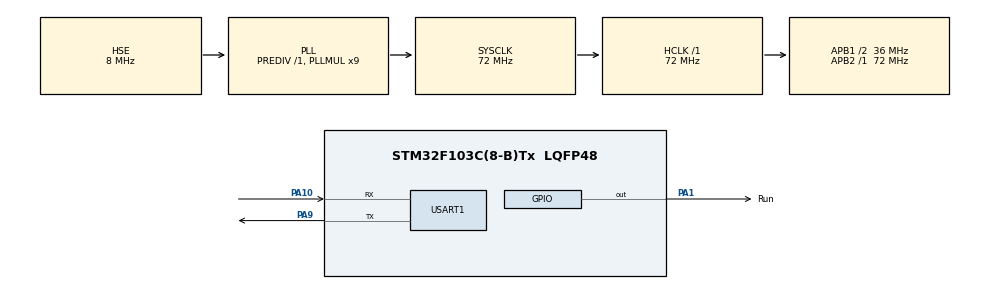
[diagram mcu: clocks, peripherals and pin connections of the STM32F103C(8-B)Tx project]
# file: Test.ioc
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Mcu.Family=STM32F1
Mcu.Name=STM32F103C(8-B)Tx
Mcu.Package=LQFP48
NVIC.PriorityGroup=NVIC_PRIORITYGROUP_4
NVIC.USART1_IRQn=true\:0\:0\:false\:false\:true\:true\:true\:true
PA1.GPIO_Label=Run
PA1.GPIO_ModeDefaultOutputPP=GPIO_MODE_OUTPUT_PP
PA1.GPIO_PuPd=GPIO_NOPULL
PA1.Signal=GPIO_Output
PA10.Mode=Asynchronous
PA10.Signal=USART1_RX
PA13.Mode=JTAG_4_pins
PA13.Signal=SYS_JTMS-SWDIO
PA14.Mode=JTAG_4_pins
PA14.Signal=SYS_JTCK-SWCLK
PA15.Mode=JTAG_4_pins
PA15.Signal=SYS_JTDI
PA9.Mode=Asynchronous
PA9.Signal=USART1_TX
PB3.Mode=JTAG_4_pins
PB3.Signal=SYS_JTDO-TRACESWO
PC14-OSC32_IN.Mode=LSE-External-Oscillator
PC14-OSC32_IN.Signal=RCC_OSC32_IN
PC15-OSC32_OUT.Mode=LSE-External-Oscillator
PC15-OSC32_OUT.Signal=RCC_OSC32_OUT
PD0-OSC_IN.Mode=HSE-External-Oscillator
PD0-OSC_IN.Signal=RCC_OSC_IN
PD1-OSC_OUT.Mode=HSE-External-Oscillator
PD1-OSC_OUT.Signal=RCC_OSC_OUT
ProjectManager.HeapSize=0x200
ProjectManager.StackSize=0x400
ProjectManager.TargetToolchain=MDK-ARM V5.32
RCC.AHBFreq_Value=72000000
RCC.APB1CLKDivider=RCC_HCLK_DIV2
RCC.APB1Freq_Value=36000000
RCC.APB1TimFreq_Value=72000000
RCC.APB2Freq_Value=72000000
RCC.APB2TimFreq_Value=72000000
RCC.HCLKFreq_Value=72000000
RCC.PLLMUL=RCC_PLL_MUL9
RCC.PLLSourceVirtual=RCC_PLLSOURCE_HSE
RCC.SYSCLKFreq_VALUE=72000000
RCC.SYSCLKSource=RCC_SYSCLKSOURCE_PLLCLK
RCC.USBFreq_Value=72000000
USART1.VirtualMode=VM_ASYNC
board=custom

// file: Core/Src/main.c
/* USER CODE BEGIN Header */
/**
  ******************************************************************************
  * @file           : main.c
  * @brief          : Main program body
  ******************************************************************************
  * @attention
  *
  * Copyright (c) 2023 STMicroelectronics.
  * All rights reserved.
  *
  * This software is licensed under terms that can be found in the LICENSE file
  * in the root directory of this software component.
  * If no LICENSE file comes with this software, it is provided AS-IS.
  *
  ******************************************************************************
  */
/* USER CODE END Header */
#include <stdio.h>
#include "main.h"
#include "usart.h"
#include "gpio.h"

/* USER CODE BEGIN PTD */
// 流水灯-用于观察单片机是否正常运行
uint32_t SysTick_Interrupt_Counter = 0;
uint8_t Toggle_Run_Led_Flag = 0;

// 串口通信-全双工
uint8_t Uart1_Rx_Buf[MAX_UART1_LENBUF] = {0};
uint16_t Uart1_Rx_Buf_p = 0;
uint16_t Uart1_Rx_Message_Num = 0;
enum Uart1_Rx_Statues{
    go_on,wait
}Uart1_Rx_Statue;
/* USER CODE END PTD */

void SystemClock_Config(void);

int main(void)
{

  /* MCU Configuration--------------------------------------------------------*/

  /* Reset of all peripherals, Initializes the Flash interface and the Systick. */
  HAL_Init();

  /* Configure the system clock */
  SystemClock_Config();

  /* Initialize all configured peripherals */
  MX_GPIO_Init();
  MX_USART1_UART_Init();
  /* USER CODE BEGIN 2 */
  // 串口接收函数起始中断
  HAL_UART_Receive_IT(&huart1,(uint8_t*)Uart1_Rx_Buf,1);
  // 设置初始状态
  Uart1_Rx_Statue = go_on;
  /* USER CODE END 2 */

  /* Infinite loop */
  while (1)
  {
    if(Toggle_Run_Led_Flag){
        Toggle_Run_Led_Flag = 0;
        HAL_GPIO_TogglePin(Run_GPIO_Port,Run_Pin);
    }
  }
}

void SystemClock_Config(void)
{
  RCC_OscInitTypeDef RCC_OscInitStruct = {0};
  RCC_ClkInitTypeDef RCC_ClkInitStruct = {0};

  /** Initializes the RCC Oscillators according to the specified parameters
  * in the RCC_OscInitTypeDef structure.
  */
  RCC_OscInitStruct.OscillatorType = RCC_OSCILLATORTYPE_HSE;
  RCC_OscInitStruct.HSEState = RCC_HSE_ON;
  RCC_OscInitStruct.HSEPredivValue = RCC_HSE_PREDIV_DIV1;
  RCC_OscInitStruct.HSIState = RCC_HSI_ON;
  RCC_OscInitStruct.PLL.PLLState = RCC_PLL_ON;
  RCC_OscInitStruct.PLL.PLLSource = RCC_PLLSOURCE_HSE;
  RCC_OscInitStruct.PLL.PLLMUL = RCC_PLL_MUL9;
  if (HAL_RCC_OscConfig(&RCC_OscInitStruct) != HAL_OK)
  {
    Error_Handler();
  }

  /** Initializes the CPU, AHB and APB buses clocks
  */
  RCC_ClkInitStruct.ClockType = RCC_CLOCKTYPE_HCLK|RCC_CLOCKTYPE_SYSCLK
                              |RCC_CLOCKTYPE_PCLK1|RCC_CLOCKTYPE_PCLK2;
  RCC_ClkInitStruct.SYSCLKSource = RCC_SYSCLKSOURCE_PLLCLK;
  RCC_ClkInitStruct.AHBCLKDivider = RCC_SYSCLK_DIV1;
  RCC_ClkInitStruct.APB1CLKDivider = RCC_HCLK_DIV2;
  RCC_ClkInitStruct.APB2CLKDivider = RCC_HCLK_DIV1;

  if (HAL_RCC_ClockConfig(&RCC_ClkInitStruct, FLASH_LATENCY_2) != HAL_OK)
  {
    Error_Handler();
  }
}

/* USER CODE BEGIN 4 */
/**
 * 接受中断回调函数
 */
void HAL_UART_RxCpltCallback(UART_HandleTypeDef *UartHandle) {
    // 数据缓冲区
    if (UartHandle == &huart1) {//如果接受到串口1的数据
        switch (Uart1_Rx_Statue) {
            case go_on:
                if (Uart1_Rx_Buf[Uart1_Rx_Buf_p] != '\r') {//非\r 非\n--保持当前状态（go_on）
                    Uart1_Rx_Buf_p++;
                    if (Uart1_Rx_Buf_p > MAX_UART1_LENBUF - 1) {//索引值从0开始
                        Uart1_Rx_Buf_p = 0;
                    }
                } else {//遇到\r--需要改变状态(go_on -> wait)
                    Uart1_Rx_Statue = wait;
                }
                break;
            case wait:
                if (Uart1_Rx_Buf[Uart1_Rx_Buf_p] != '\n') {//等待\n-保持当前状态(wait)
                    //保持当前Statue
                } else {//遇见\n--需要改变状态(wait -> go_on)
                    Uart1_Rx_Message_Num++;
                    Uart1_Rx_Buf_p++;
                    if (Uart1_Rx_Buf_p > MAX_UART1_LENBUF - 1) {//索引值从0开始
                        Uart1_Rx_Buf_p = 0;
                    }
                    //状态设置为继续
                    Uart1_Rx_Statue = go_on;
                }
                break;
            default:
                break;
        }
        //中断
        HAL_UART_Receive_IT(&huart1, &Uart1_Rx_Buf[Uart1_Rx_Buf_p], 1);
    }
}
/**
   * Function_Definition
   * SysTick_Interrupt_Server
   */
void Set_Flag_Regularly_Interrupt_Server(void){
    SysTick_Interrupt_Counter++;
    if(SysTick_Interrupt_Counter%1000==0){
        Toggle_Run_Led_Flag = 1;
    }
}
/* USER CODE END 4 */

void Error_Handler(void)
{
  __disable_irq();
  while (1)
  {
  }
}
